# R7FA6E2BB register map
Vendor: Renesas Electronics Corporation; Series: RA6; File version: 1.10.01
CPU: CM33 r0p4, little endian, MPU, FPU, VTOR, 4 interrupt priority bits, 96 interrupts
Registers are 32-bit, read-write, reset 0x0 unless marked. A register's access mark holds for its fields unless they carry their own. Offsets are from the block's base; [hi:lo] are bit positions; {n}, {i} and the like mark numbered series; 'fields as' and 'values as' point back to an identical list.

## ELC — Event Link Controller
Base 0x40082000
0x00 ELCR 8-bit — Event Link Controller Register
  [7] ELCON — All Event Link Enable
    0=ELC function is disabled; 1=ELC function is enabled
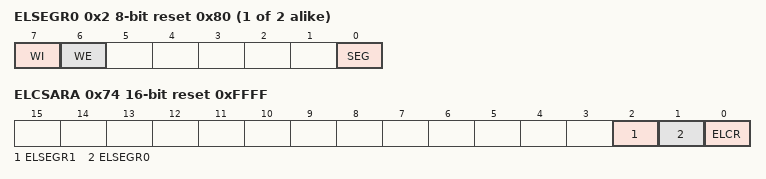
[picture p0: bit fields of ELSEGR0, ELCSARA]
{0x2+2i} ELSEGR{i} (i=0..1) 8-bit reset 0x80 — Event Link Software Event Generation Register {i}
  [7] WI wo — ELSEGR Register Write Disable
    0=Write to ELSEGR register enabled; 1=Write to ELSEGR register disabled
  [6] WE — SEG Bit Write Enable
    0=Write to SEG bit disabled; 1=Write to SEG bit enabled
  [0] SEG wo — Software Event Generation
    0=Normal operation; 1=Software event is generated
{0x10+4i} ELSR{i} (i=0..9) 16-bit — Event Link Setting Register {i}
  [8:0] ELS — Event Link Select
{0x10+4i} ELSR{i} (i=12..17) 16-bit — Event Link Setting Register {i}
  [8:0] ELS — Event Link Select
0x6C ELSR23 16-bit — Event Link Setting Register 23
  [8:0] ELS — Event Link Select
0x74 ELCSARA 16-bit reset 0xFFFF — Event Link Controller Security Attribution Register A
  [all] fields
    0=Secure; 1=Non-secure
  [2] ELSEGR1 — Event Link Software Event Generation Register 1 Security Attribution
  [1] ELSEGR0 — Event Link Software Event Generation Register 0 Security Attribution
  [0] ELCR — Event Link Controller Register Security Attribution
0x78 ELCSARB 16-bit reset 0xFFFF — Event Link Controller Security Attribution Register B
  [15:0] ELSR — Event Link Setting Register n Security Attribution
    0=Secure; 1=Non-secure
0x7C ELCSARC 16-bit reset 0xFFFF — Event Link Controller Security Attribution Register C
  [7:0] ELSR — Event Link Setting Register n Security Attribution (n = 16 to 23)
    0=Secure; 1=Non-secure

## IWDT — Independent Watchdog Timer
Base 0x40083200
0x00 IWDTRR 8-bit reset 0xFF — IWDT Refresh Register
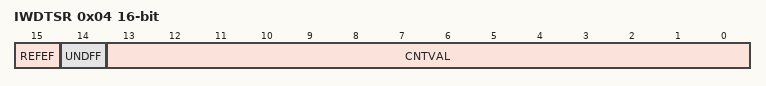
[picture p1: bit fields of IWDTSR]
0x04 IWDTSR 16-bit — IWDT Status Register
  [15] REFEF — Refresh Error Flag
    0=No refresh error occurred; 1=Refresh error occurred
  [14] UNDFF — Underflow Flag
    0=No underflow occurred; 1=Underflow occurred
  [13:0] CNTVAL ro — Down-counter Value

## WDT — Watchdog Timer
Base 0x40083400
0x00 WDTRR 8-bit reset 0xFF — WDT Refresh Register
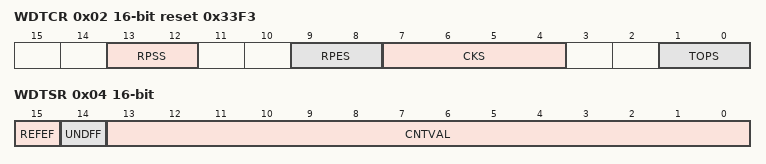
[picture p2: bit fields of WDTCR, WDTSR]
0x02 WDTCR 16-bit reset 0x33F3 — WDT Control Register
  [13:12] RPSS — Window Start Position Select
    0=25%; 1=50%; 2=75%; 3=100% (do not specify window start position)
  [9:8] RPES — Window End Position Select
    0=75%; 1=50%; 2=25%; 3=0% (do not specify window end position)
  [7:4] CKS — Clock Division Ratio Select
    1=PCLKB/4; 4=PCLKB/64; 15=PCLKB/128; 6=PCLKB/512; 7=PCLKB/2048; 8=PCLKB/8192; other=Others (Setting prohibited)
  [1:0] TOPS — Timeout Period Select
    0=1024 cycles (0x03FF); 1=4096 cycles (0x0FFF); 2=8192 cycles (0x1FFF); 3=16384 cycles (0x3FFF)
0x04 WDTSR 16-bit — WDT Status Register
  [15] REFEF — Refresh Error Flag
    0=No refresh error occurred; 1=Refresh error occurred
  [14] UNDFF — Underflow Flag
    0=No underflow occurred; 1=Underflow occurred
  [13:0] CNTVAL ro — Down-Counter Value
0x06 WDTRCR 8-bit reset 0x80 — WDT Reset Control Register
  [7] RSTIRQS — WDT Behavior Selection
    0=Interrupt; 1=Reset
0x08 WDTCSTPR 8-bit reset 0x80 — WDT Count Stop Control Register
  [7] SLCSTP — Sleep-Mode Count Stop Control Register
    0=Disable count stop; 1=Stop count on transition to Sleep mode

## CAC — Clock Frequency Accuracy Measurement Circuit
Base 0x40083600
0x00 CACR0 8-bit — CAC Control Register 0
  [0] CFME — Clock Frequency Measurement Enable
    0=Disable; 1=Enable
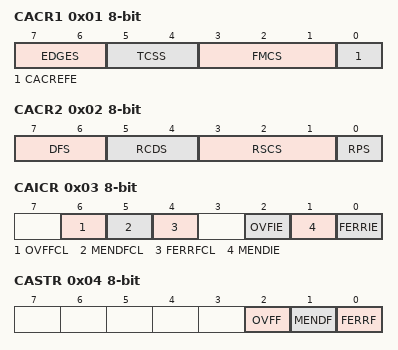
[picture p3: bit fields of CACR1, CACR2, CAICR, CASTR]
0x01 CACR1 8-bit — CAC Control Register 1
  [7:6] EDGES — Valid Edge Select
    0=Rising edge; 1=Falling edge; 2=Both rising and falling edges; 3=Setting prohibited
  [5:4] TCSS — Timer Count Clock Source Select
    0=No division; 1=x 1/4 clock; 2=x 1/8 clock; 3=x 1/32 clock
  [3:1] FMCS — Measurement Target Clock Select
    0=Main clock oscillator; 1=Sub-clock oscillator; 2=HOCO clock; 3=MOCO clock; 4=LOCO clock; 5=Peripheral module clock B (PCLKB); 6=IWDT-dedicated clock; 7=Setting prohibited
  [0] CACREFE — CACREF Pin Input Enable
    0=Disable; 1=Enable
0x02 CACR2 8-bit — CAC Control Register 2
  [7:6] DFS — Digital Filter Select
    0=Disable digital filtering; 1=Use sampling clock for the digital filter as the frequency measuring clock; 2=Use sampling clock for the digital filter as the frequency measuring clock divided by 4; 3=Use sampling clock for the digital filter as the frequency measuring clock divided by 16
  [5:4] RCDS — Measurement Reference Clock Frequency Division Ratio Select
    0=x 1/32 clock; 1=x 1/128 clock; 2=x 1/1024 clock; 3=x 1/8192 clock
  [3:1] RSCS — Measurement Reference Clock Select
    values as CACR1.FMCS
  [0] RPS — Reference Signal Select
    0=CACREF pin input; 1=Internal clock (internally generated signal)
0x03 CAICR 8-bit — CAC Interrupt Control Register
  [6] OVFFCL wo — OVFF Clear
    0=No effect; 1=The CASTR.OVFF flag is cleared
  [5] MENDFCL wo — MENDF Clear
    0=No effect; 1=The CASTR.MENDF flag is cleared
  [4] FERRFCL wo — FERRF Clear
    0=No effect; 1=The CASTR.FERRF flag is cleared
  [2] OVFIE — Overflow Interrupt Request Enable
    0=Disable; 1=Enable
  [1] MENDIE — Measurement End Interrupt Request Enable
    0=Disable; 1=Enable
  [0] FERRIE — Frequency Error Interrupt Request Enable
    0=Disable; 1=Enable
0x04 CASTR 8-bit ro — CAC Status Register
  [2] OVFF — Overflow Flag
    0=Counter has not overflowed; 1=Counter overflowed
  [1] MENDF — Measurement End Flag
    0=Measurement is in progress; 1=Measurement ended
  [0] FERRF — Frequency Error Flag
    0=Clock frequency is within the allowable range; 1=Clock frequency has deviated beyond the allowable range (frequency error)
0x06 CAULVR 16-bit — CAC Upper-Limit Value Setting Register
0x08 CALLVR 16-bit — CAC Lower-Limit Value Setting Register
0x0A CACNTBR 16-bit ro — CAC Counter Buffer Register
